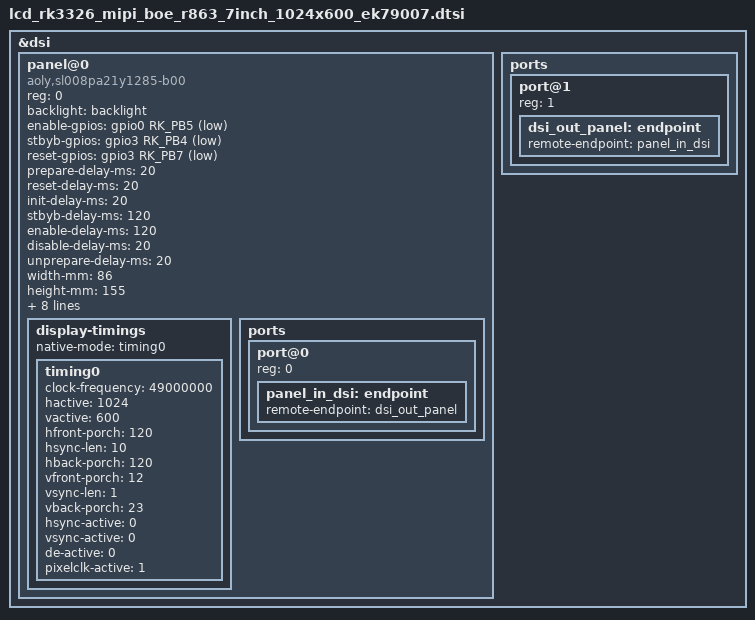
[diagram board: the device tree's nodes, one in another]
/*
* incar mipi lcd
*/
&dsi {
	status = "okay";

	panel@0 {
		compatible = "aoly,sl008pa21y1285-b00", "simple-panel-dsi";
		reg = <0>;
		backlight = <&backlight>;
		enable-gpios = <&gpio0 RK_PB5 GPIO_ACTIVE_LOW>;
		stbyb-gpios = <&gpio3 RK_PB4 GPIO_ACTIVE_LOW>;
		
		reset-gpios = <&gpio3 RK_PB7 GPIO_ACTIVE_LOW>;
		prepare-delay-ms = <20>;
		reset-delay-ms = <20>;
		init-delay-ms = <20>;
		stbyb-delay-ms = <120>;
		enable-delay-ms = <120>;
		disable-delay-ms = <20>;
		unprepare-delay-ms = <20>;

		width-mm = <86>;
		height-mm = <155>;

		dsi,flags = <(MIPI_DSI_MODE_VIDEO | MIPI_DSI_MODE_VIDEO_BURST |
			      MIPI_DSI_MODE_LPM | MIPI_DSI_MODE_EOT_PACKET)>;
		dsi,format = <MIPI_DSI_FMT_RGB888>;
		dsi,lanes = <4>;

		panel-init-sequence = [
			/*15 00 02 B2 10
			15 00 02 80 58
			15 00 02 81 47
			15 00 02 82 D4
			15 00 02 83 88
			15 00 02 84 A9
			15 00 02 85 C3
			15 00 02 86 82*/
			/*05 1e 01 01
			15 00 02 80 AC
			15 00 02 81 B8
			15 00 02 82 09
			15 00 02 83 78
			15 00 02 84 7F
			15 00 02 85 BB
			15 78 02 86 70*/
			05 78 01 11
			05 05 01 29
		];

		panel-exit-sequence = [
			05 00 01 28
			05 00 01 10
		];

				
		display-timings {
			native-mode = <&timing0>;

			timing0: timing0 {
				clock-frequency = <49000000>;
				hactive = <1024>;
				vactive = <600>;
				hfront-porch = <120>;
				hsync-len = <10>;
				hback-porch = <120>;
				vfront-porch = <12>;
				vsync-len = <1>;
				vback-porch = <23>;
				hsync-active = <0>;
				vsync-active = <0>;
				de-active = <0>;
				pixelclk-active = <1>;
			};
		};
		ports {
			#address-cells = <1>;
			#size-cells = <0>;

			port@0 {
				reg = <0>;
				panel_in_dsi: endpoint {
					remote-endpoint = <&dsi_out_panel>;
				};
			};
		};
	};

	ports {
		#address-cells = <1>;
		#size-cells = <0>;

		port@1 {
			reg = <1>;
			dsi_out_panel: endpoint {
				remote-endpoint = <&panel_in_dsi>;
			};
		};
	};
};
